# ESP32-S31 register map
Vendor: ESPRESSIF SYSTEMS (SHANGHAI) CO., LTD.; Series: ESP32 S-Series; File version: 1
CPU: RV32IMAFC r0p0, little endian, no MPU, FPU, 0 interrupt priority bits
Address unit: 32 bits
Registers are 32-bit, read-write, reset 0x0 unless marked. A register's access mark holds for its fields unless they carry their own. Offsets are from the block's base; [hi:lo] are bit positions; {n}, {i} and the like mark numbered series.

## ICM_SYS — ICM AXI Interconnect System
Base 0x20510000
0x400 DATE reset 0x15FBA94
  [31:0] REG_DATE
0x404 CLK_EN
  [0] REG_CLK_EN
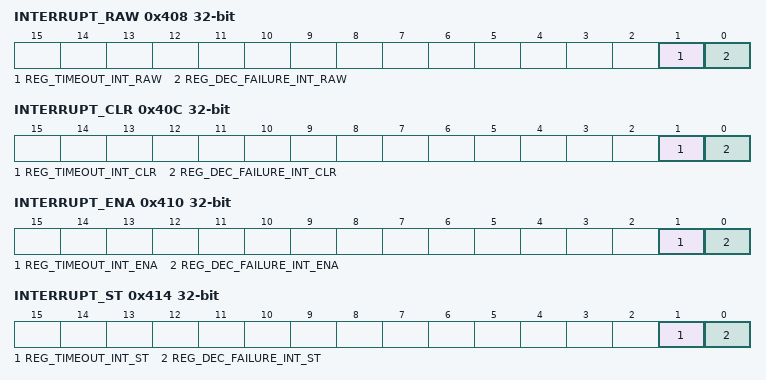
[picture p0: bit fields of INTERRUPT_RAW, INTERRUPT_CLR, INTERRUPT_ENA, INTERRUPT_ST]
0x408 INTERRUPT_RAW
  [1] REG_TIMEOUT_INT_RAW, [0] REG_DEC_FAILURE_INT_RAW
0x40C INTERRUPT_CLR wo
  [1] REG_TIMEOUT_INT_CLR, [0] REG_DEC_FAILURE_INT_CLR
0x410 INTERRUPT_ENA
  [1] REG_TIMEOUT_INT_ENA, [0] REG_DEC_FAILURE_INT_ENA
0x414 INTERRUPT_ST ro
  [1] REG_TIMEOUT_INT_ST, [0] REG_DEC_FAILURE_INT_ST
0x418 TIMEOUT_MAX_CNT reset 0xFFFFFFFF
  [31:0] REG_TIMEOUT_MAX_CNT
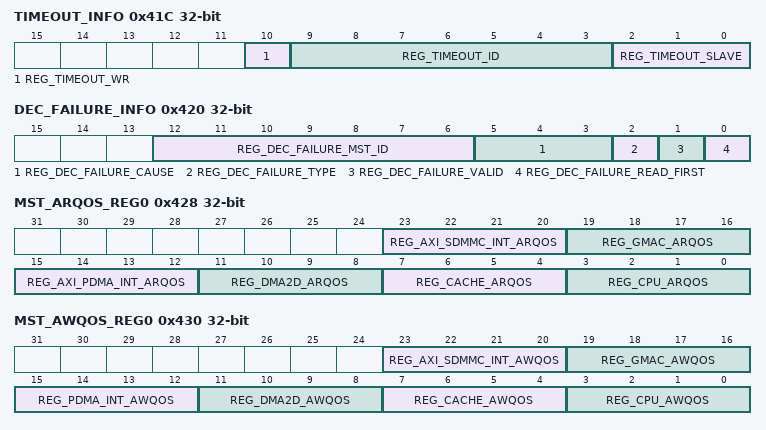
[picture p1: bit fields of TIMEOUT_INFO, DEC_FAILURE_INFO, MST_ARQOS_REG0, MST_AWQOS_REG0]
0x41C TIMEOUT_INFO ro
  [10] REG_TIMEOUT_WR, [9:3] REG_TIMEOUT_ID, [2:0] REG_TIMEOUT_SLAVE
0x420 DEC_FAILURE_INFO access per field
  [12:6] REG_DEC_FAILURE_MST_ID ro, [5:3] REG_DEC_FAILURE_CAUSE ro, [2] REG_DEC_FAILURE_TYPE ro, [1] REG_DEC_FAILURE_VALID ro, [0] REG_DEC_FAILURE_READ_FIRST rw
0x424 QOS_DEBUG_MST_SEL
  [3:0] REG_QOS_DEBUG_MST_SEL
0x428 MST_ARQOS_REG0
  [23:20] REG_AXI_SDMMC_INT_ARQOS, [19:16] REG_GMAC_ARQOS, [15:12] REG_AXI_PDMA_INT_ARQOS, [11:8] REG_DMA2D_ARQOS, [7:4] REG_CACHE_ARQOS, [3:0] REG_CPU_ARQOS
0x430 MST_AWQOS_REG0
  [23:20] REG_AXI_SDMMC_INT_AWQOS, [19:16] REG_GMAC_AWQOS, [15:12] REG_PDMA_INT_AWQOS, [11:8] REG_DMA2D_AWQOS, [7:4] REG_CACHE_AWQOS, [3:0] REG_CPU_AWQOS
0x480 DEC_FAILURE_ADDR ro
  [31:0] REG_DEC_FAILURE_ADDR
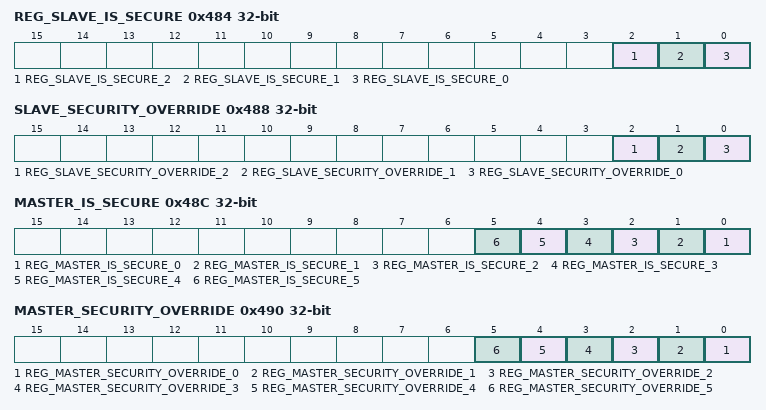
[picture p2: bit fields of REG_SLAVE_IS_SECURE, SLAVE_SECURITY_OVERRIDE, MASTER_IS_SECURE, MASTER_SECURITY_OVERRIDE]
0x484 REG_SLAVE_IS_SECURE
  [2] REG_SLAVE_IS_SECURE_2, [1] REG_SLAVE_IS_SECURE_1, [0] REG_SLAVE_IS_SECURE_0
0x488 SLAVE_SECURITY_OVERRIDE
  [2] REG_SLAVE_SECURITY_OVERRIDE_2, [1] REG_SLAVE_SECURITY_OVERRIDE_1, [0] REG_SLAVE_SECURITY_OVERRIDE_0
0x48C MASTER_IS_SECURE
  [n] REG_MASTER_IS_SECURE_{n} (n=0..5)
0x490 MASTER_SECURITY_OVERRIDE
  [n] REG_MASTER_SECURITY_OVERRIDE_{n} (n=0..5)
{0x494+4i} AW_QOS_VALUE{i} (i=0..5)
  [3:0] REG_AW_QOS_VALUE_0
{0x4AC+4i} AR_QOS_VALUE{i} (i=0..5)
  [3:0] REG_AR_QOS_VALUE_0
{0x4C4+4i} B_PRIOR_VALUE{i} (i=0..2)
  [3:0] REG_B_PRIOR_VALUE_0
{0x4D0+4i} R_PRIOR_VALUE{i} (i=0..2)
  [3:0] REG_R_PRIOR_VALUE_0
{0x4DC+4i} AW_QOS_SEL{i} (i=0..5)
  [1:0] REG_AW_QOS_SEL_0
{0x4F4+4i} AR_QOS_SEL{i} (i=0..5)
  [1:0] REG_AR_QOS_SEL_0
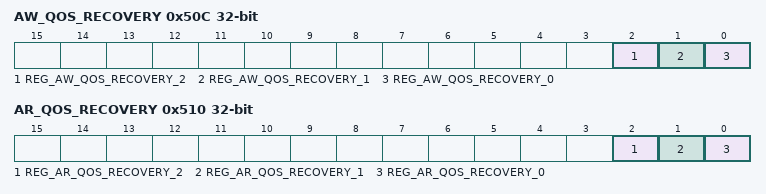
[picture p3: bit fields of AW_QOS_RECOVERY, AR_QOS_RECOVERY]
0x50C AW_QOS_RECOVERY
  [2] REG_AW_QOS_RECOVERY_2, [1] REG_AW_QOS_RECOVERY_1, [0] REG_AW_QOS_RECOVERY_0
0x510 AR_QOS_RECOVERY
  [2] REG_AR_QOS_RECOVERY_2, [1] REG_AR_QOS_RECOVERY_1, [0] REG_AR_QOS_RECOVERY_0
{0x514+4i} AW_QOS_ID_MASK{i} (i=0..5) reset 0xF
  [3:0] REG_AW_QOS_ID_MASK_0
{0x52C+4i} AR_QOS_ID_MASK{i} (i=0..5) reset 0xF
  [3:0] REG_AR_QOS_ID_MASK_0
{0x544+4i} AW_QOS_ID_FILTER{i} (i=0..5) reset 0xF
  [3:0] REG_AW_QOS_ID_FILTER_0
{0x55C+4i} AR_QOS_ID_FILTER{i} (i=0..5) reset 0xF
  [3:0] REG_AR_QOS_ID_FILTER_0
{0x574+4i} AW_QOS_CTRL_CFG{i} (i=0..5) reset 0x2010
  [31:0] REG_AW_QOS_CTRL_CFG_0
{0x58C+4i} AR_QOS_CTRL_CFG{i} (i=0..5) reset 0x2010
  [31:0] REG_AR_QOS_CTRL_CFG_0
{0x5A4+4i} AW_QOS_TRANS_RATE{i} (i=0..5) reset 0x3008
  [15:0] REG_AW_QOS_TRANS_RATE_0
{0x5BC+4i} AR_QOS_TRANS_RATE{i} (i=0..5) reset 0x3008
  [15:0] REG_AR_QOS_TRANS_RATE_0
{0x5D4+4i} AW_QOS_PEAK_RATE{i} (i=0..5)
  [7:0] REG_AW_QOS_PEAK_RATE_0
{0x5EC+4i} AR_QOS_PEAK_RATE{i} (i=0..5)
  [7:0] REG_AR_QOS_PEAK_RATE_0
{0x604+4i} AW_QOS_BURSTINESS{i} (i=0..5) reset 0x80
  [11:0] REG_AW_QOS_BURSTINESS_0
{0x61C+4i} AR_QOS_BURSTINESS{i} (i=0..5) reset 0x80
  [11:0] REG_AR_QOS_BURSTINESS_0
{0x634+4i} AW_QOS_CFG_VLU{i} (i=0..5) reset 0xDA62
  [15:0] REG_AW_QOS_CFG_VLU_0
{0x64C+4i} AR_QOS_CFG_VLU{i} (i=0..5) reset 0xDA62
  [15:0] REG_AR_QOS_CFG_VLU_0
{0x664+4i} AW_QOS_DLY_THR0{i} (i=0..5) reset 0x20
  [12:0] REG_AW_QOS_DLY_THR0_0
{0x67C+4i} AW_QOS_DLY_THR1{i} (i=0..5) reset 0xA0
  [12:0] REG_AW_QOS_DLY_THR1_0
{0x694+4i} AW_QOS_DLY_THR2{i} (i=0..5) reset 0x1A0
  [12:0] REG_AW_QOS_DLY_THR2_0
{0x6AC+4i} AW_QOS_DLY_THR3{i} (i=0..5) reset 0x3A0
  [12:0] REG_AW_QOS_DLY_THR3_0
{0x6C4+4i} AR_QOS_DLY_THR0{i} (i=0..5) reset 0x20
  [12:0] REG_AR_QOS_DLY_THR0_0
{0x6DC+4i} AR_QOS_DLY_THR1{i} (i=0..5) reset 0xA0
  [12:0] REG_AR_QOS_DLY_THR1_0
{0x6F4+4i} AR_QOS_DLY_THR2{i} (i=0..5) reset 0x1A0
  [12:0] REG_AR_QOS_DLY_THR2_0
{0x70C+4i} AR_QOS_DLY_THR3{i} (i=0..5) reset 0x3A0
  [12:0] REG_AR_QOS_DLY_THR3_0
{0x724+4i} AW_QOS_BUR_LEN_THR{i} (i=0..5) reset 0x40
  [9:0] REG_AW_QOS_BUR_LEN_THR_0
{0x73C+4i} AR_QOS_BUR_LEN_THR{i} (i=0..5) reset 0x40
  [9:0] REG_AR_QOS_BUR_LEN_THR_0
{0x754+4i} AW_QOS_DBG_TK_THR{i} (i=0..5) reset 0x10
  [7:0] REG_AW_QOS_DBG_TK_THR_0
{0x76C+4i} AR_QOS_DBG_TK_THR{i} (i=0..5) reset 0x10
  [7:0] REG_AR_QOS_DBG_TK_THR_0
{0x784+4i} MAX_OST_AW_S{i} (i=0..2) reset 0xF
  [5:0] REG_MAX_OST_AW_S_0
{0x790+4i} MAX_OST_AR_S{i} (i=0..2) reset 0xF
  [7:0] REG_MAX_OST_AR_S_0
0x79C AW_QOS_PEAK_RATE_MODE
  [5:0] REG_AW_QOS_PEAK_RATE_MODE
0x7A0 AR_QOS_PEAK_RATE_MODE
  [5:0] REG_AR_QOS_PEAK_RATE_MODE
